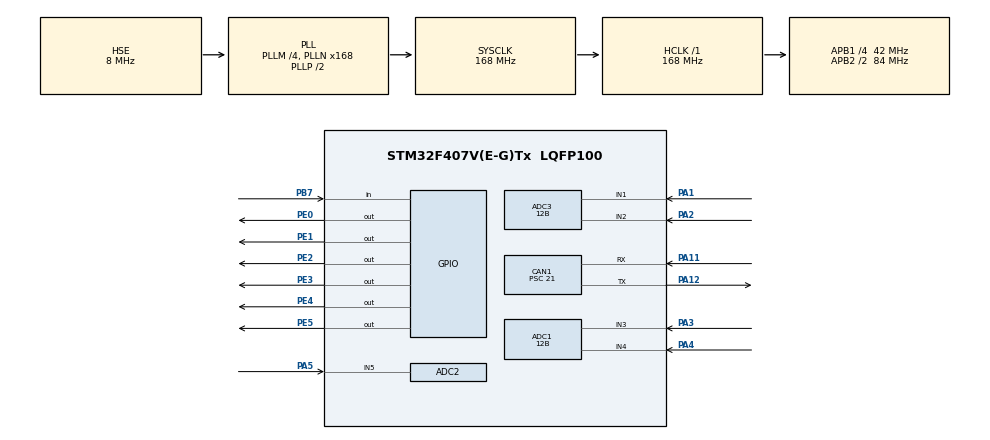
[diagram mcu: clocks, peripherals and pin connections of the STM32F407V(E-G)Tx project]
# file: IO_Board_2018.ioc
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ADC1.Channel-0\#ChannelRegularConversion=ADC_CHANNEL_3
ADC1.Channel-1\#ChannelRegularConversion=ADC_CHANNEL_4
ADC1.ClockPrescaler=ADC_CLOCK_SYNC_PCLK_DIV4
ADC1.ContinuousConvMode=DISABLE
ADC1.DMAContinuousRequests=DISABLE
ADC1.DataAlign=ADC_DATAALIGN_RIGHT
ADC1.DiscontinuousConvMode=ENABLE
ADC1.EOCSelection=ADC_EOC_SINGLE_CONV
ADC1.EnableAnalogWatchDog=false
ADC1.ExternalTrigConv=ADC_SOFTWARE_START
ADC1.ExternalTrigConvEdge=ADC_EXTERNALTRIGCONVEDGE_NONE
ADC1.InjNumberOfConversion=0
ADC1.NbrOfConversion=2
ADC1.NbrOfConversionFlag=1
ADC1.NbrOfDiscConversion=1
ADC1.Rank-0\#ChannelRegularConversion=1
ADC1.Rank-1\#ChannelRegularConversion=2
ADC1.Resolution=ADC_RESOLUTION_12B
ADC1.SamplingTime-0\#ChannelRegularConversion=ADC_SAMPLETIME_3CYCLES
ADC1.SamplingTime-1\#ChannelRegularConversion=ADC_SAMPLETIME_3CYCLES
ADC1.ScanConvMode=ENABLE
ADC1.master=1
ADC2.Channel-0\#ChannelRegularConversion=ADC_CHANNEL_5
ADC2.ClockPrescaler=ADC_CLOCK_SYNC_PCLK_DIV4
ADC2.ContinuousConvMode=DISABLE
ADC2.DMAContinuousRequests=DISABLE
ADC2.DataAlign=ADC_DATAALIGN_RIGHT
ADC2.DiscontinuousConvMode=DISABLE
ADC2.EOCSelection=ADC_EOC_SEQ_CONV
ADC2.EnableAnalogWatchDog=false
ADC2.ExternalTrigConv=ADC_SOFTWARE_START
ADC2.ExternalTrigConvEdge=ADC_EXTERNALTRIGCONVEDGE_NONE
ADC2.InjNumberOfConversion=0
ADC2.NbrOfConversion=1
ADC2.NbrOfConversionFlag=1
ADC2.Rank-0\#ChannelRegularConversion=1
ADC2.Resolution=ADC_RESOLUTION_12B
ADC2.SamplingTime-0\#ChannelRegularConversion=ADC_SAMPLETIME_3CYCLES
ADC2.ScanConvMode=DISABLE
ADC3.Channel-0\#ChannelRegularConversion=ADC_CHANNEL_1
ADC3.Channel-1\#ChannelRegularConversion=ADC_CHANNEL_2
ADC3.ClockPrescaler=ADC_CLOCK_SYNC_PCLK_DIV4
ADC3.ContinuousConvMode=DISABLE
ADC3.DMAContinuousRequests=DISABLE
ADC3.DataAlign=ADC_DATAALIGN_RIGHT
ADC3.DiscontinuousConvMode=ENABLE
ADC3.EOCSelection=ADC_EOC_SINGLE_CONV
ADC3.EnableAnalogWatchDog=false
ADC3.ExternalTrigConv=ADC_SOFTWARE_START
ADC3.ExternalTrigConvEdge=ADC_EXTERNALTRIGCONVEDGE_NONE
ADC3.InjNumberOfConversion=0
ADC3.NbrOfConversion=2
ADC3.NbrOfConversionFlag=1
ADC3.Rank-0\#ChannelRegularConversion=1
ADC3.Rank-1\#ChannelRegularConversion=2
ADC3.Resolution=ADC_RESOLUTION_12B
ADC3.SamplingTime-0\#ChannelRegularConversion=ADC_SAMPLETIME_3CYCLES
ADC3.SamplingTime-1\#ChannelRegularConversion=ADC_SAMPLETIME_3CYCLES
ADC3.ScanConvMode=ENABLE
CAN1.CalculateTimeBit=1500
CAN1.CalculateTimeQuantum=500.0
CAN1.Prescaler=21
CAN1.TimeSeg1=CAN_BS1_2TQ
CAN1.TimeSeg2=CAN_BS2_2TQ
Mcu.Family=STM32F4
Mcu.Name=STM32F407V(E-G)Tx
Mcu.Package=LQFP100
NVIC.PriorityGroup=NVIC_PRIORITYGROUP_4
PA1.Signal=ADCx_IN1
PA11.Mode=Master
PA11.Signal=CAN1_RX
PA12.Mode=Master
PA12.Signal=CAN1_TX
PA13.Mode=Serial_Wire
PA13.Signal=SYS_JTMS-SWDIO
PA14.Mode=Serial_Wire
PA14.Signal=SYS_JTCK-SWCLK
PA2.Signal=ADCx_IN2
PA3.Signal=ADCx_IN3
PA4.Signal=ADCx_IN4
PA5.Signal=ADCx_IN5
PB7.Signal=GPIO_Input
PE0.Signal=GPIO_Output
PE1.Signal=GPIO_Output
PE2.Signal=GPIO_Output
PE3.Signal=GPIO_Output
PE4.Signal=GPIO_Output
PE5.Signal=GPIO_Output
PH0-OSC_IN.Mode=HSE-External-Oscillator
PH0-OSC_IN.Signal=RCC_OSC_IN
PH1-OSC_OUT.Mode=HSE-External-Oscillator
PH1-OSC_OUT.Signal=RCC_OSC_OUT
ProjectManager.HeapSize=0x200
ProjectManager.StackSize=0x400
ProjectManager.TargetToolchain=TrueSTUDIO
RCC.48MHZClocksFreq_Value=84000000
RCC.AHBFreq_Value=168000000
RCC.APB1CLKDivider=RCC_HCLK_DIV4
RCC.APB1Freq_Value=42000000
RCC.APB1TimFreq_Value=84000000
RCC.APB2CLKDivider=RCC_HCLK_DIV2
RCC.APB2Freq_Value=84000000
RCC.APB2TimFreq_Value=168000000
RCC.CortexFreq_Value=168000000
RCC.HCLKFreq_Value=168000000
RCC.HSE_VALUE=8000000
RCC.HSI_VALUE=16000000
RCC.LSE_VALUE=32768
RCC.PLLM=4
RCC.PLLN=168
RCC.PLLSourceVirtual=RCC_PLLSOURCE_HSE
RCC.SYSCLKFreq_VALUE=168000000
RCC.SYSCLKSource=RCC_SYSCLKSOURCE_PLLCLK
RCC.VCOOutputFreq_Value=336000000
SH.ADCx_IN1.0=ADC3_IN1,IN1
SH.ADCx_IN2.0=ADC3_IN2,IN2
SH.ADCx_IN3.0=ADC1_IN3,IN3
SH.ADCx_IN4.0=ADC1_IN4,IN4
SH.ADCx_IN5.0=ADC2_IN5,IN5
board=IO_Board_2018

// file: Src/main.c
/**
  ******************************************************************************
  * @file           : main.c
  * @brief          : Main program body
  ******************************************************************************
  ** This notice applies to any and all portions of this file
  * that are not between comment pairs USER CODE BEGIN and
  * USER CODE END. Other portions of this file, whether
  * inserted by the user or by software development tools
  * are owned by their respective copyright owners.
  *
  * COPYRIGHT(c) 2018 STMicroelectronics
  *
  * Redistribution and use in source and binary forms, with or without modification,
  * are permitted provided that the following conditions are met:
  *   1. Redistributions of source code must retain the above copyright notice,
  *      this list of conditions and the following disclaimer.
  *   2. Redistributions in binary form must reproduce the above copyright notice,
  *      this list of conditions and the following disclaimer in the documentation
  *      and/or other materials provided with the distribution.
  *   3. Neither the name of STMicroelectronics nor the names of its contributors
  *      may be used to endorse or promote products derived from this software
  *      without specific prior written permission.
  *
  * THIS SOFTWARE IS PROVIDED BY THE COPYRIGHT HOLDERS AND CONTRIBUTORS "AS IS"
  * AND ANY EXPRESS OR IMPLIED WARRANTIES, INCLUDING, BUT NOT LIMITED TO, THE
  * IMPLIED WARRANTIES OF MERCHANTABILITY AND FITNESS FOR A PARTICULAR PURPOSE ARE
  * DISCLAIMED. IN NO EVENT SHALL THE COPYRIGHT HOLDER OR CONTRIBUTORS BE LIABLE
  * FOR ANY DIRECT, INDIRECT, INCIDENTAL, SPECIAL, EXEMPLARY, OR CONSEQUENTIAL
  * DAMAGES (INCLUDING, BUT NOT LIMITED TO, PROCUREMENT OF SUBSTITUTE GOODS OR
  * SERVICES; LOSS OF USE, DATA, OR PROFITS; OR BUSINESS INTERRUPTION) HOWEVER
  * CAUSED AND ON ANY THEORY OF LIABILITY, WHETHER IN CONTRACT, STRICT LIABILITY,
  * OR TORT (INCLUDING NEGLIGENCE OR OTHERWISE) ARISING IN ANY WAY OUT OF THE USE
  * OF THIS SOFTWARE, EVEN IF ADVISED OF THE POSSIBILITY OF SUCH DAMAGE.
  *
  ******************************************************************************
  */
#include "main.h"
#include "stm32f4xx_hal.h"
#include "adc.h"
#include "can.h"
#include "gpio.h"

/* USER CODE BEGIN Includes */
#include "io.h"
#include "scheduler.h"

ADC_HandleTypeDef hadc1;
ADC_HandleTypeDef hadc2;
ADC_HandleTypeDef hadc3;
/* USER CODE END Includes */

/* USER CODE BEGIN PV */
/* Private variables ---------------------------------------------------------*/

/* USER CODE END PV */

void SystemClock_Config(void);

/* USER CODE BEGIN PFP */
/* Private function prototypes -----------------------------------------------*/

/* USER CODE END PFP */

int main(void)
{

  /* MCU Configuration----------------------------------------------------------*/

  /* Reset of all peripherals, Initializes the Flash interface and the Systick. */
  HAL_Init();

  /* Configure the system clock */
  SystemClock_Config();

  /* Initialize all configured peripherals */
  MX_GPIO_Init();
  MX_ADC1_Init();
  MX_ADC2_Init();
  MX_ADC3_Init();
  MX_CAN1_Init();
  /* USER CODE BEGIN 2 */
  Init_MyCAN();
  init();
  Schedule schedule;
  MakeSchedule(&schedule, 3);
  AddTask(&schedule, &mainLoop, 437);
  AddTask(&schedule, &sendCANStatuses, 758);
  AddTask(&schedule, &sendHeartbeat, 1000);
  /* USER CODE END 2 */

  /* Infinite loop */
  /* USER CODE BEGIN WHILE */
  while (1)
  {
	  RunSchedule(&schedule);
  }
  /* USER CODE END WHILE */

  /* USER CODE BEGIN 3 */
  DeleteSchedule(schedule);
  /* USER CODE END 3 */

}

void SystemClock_Config(void)
{

  RCC_OscInitTypeDef RCC_OscInitStruct;
  RCC_ClkInitTypeDef RCC_ClkInitStruct;

    /**Configure the main internal regulator output voltage
    */
  __HAL_RCC_PWR_CLK_ENABLE();

  __HAL_PWR_VOLTAGESCALING_CONFIG(PWR_REGULATOR_VOLTAGE_SCALE1);

    /**Initializes the CPU, AHB and APB busses clocks
    */
  RCC_OscInitStruct.OscillatorType = RCC_OSCILLATORTYPE_HSE;
  RCC_OscInitStruct.HSEState = RCC_HSE_ON;
  RCC_OscInitStruct.PLL.PLLState = RCC_PLL_ON;
  RCC_OscInitStruct.PLL.PLLSource = RCC_PLLSOURCE_HSE;
  RCC_OscInitStruct.PLL.PLLM = 4;
  RCC_OscInitStruct.PLL.PLLN = 168;
  RCC_OscInitStruct.PLL.PLLP = RCC_PLLP_DIV2;
  RCC_OscInitStruct.PLL.PLLQ = 4;
  if (HAL_RCC_OscConfig(&RCC_OscInitStruct) != HAL_OK)
  {
    _Error_Handler(__FILE__, __LINE__);
  }

    /**Initializes the CPU, AHB and APB busses clocks
    */
  RCC_ClkInitStruct.ClockType = RCC_CLOCKTYPE_HCLK|RCC_CLOCKTYPE_SYSCLK
                              |RCC_CLOCKTYPE_PCLK1|RCC_CLOCKTYPE_PCLK2;
  RCC_ClkInitStruct.SYSCLKSource = RCC_SYSCLKSOURCE_PLLCLK;
  RCC_ClkInitStruct.AHBCLKDivider = RCC_SYSCLK_DIV1;
  RCC_ClkInitStruct.APB1CLKDivider = RCC_HCLK_DIV4;
  RCC_ClkInitStruct.APB2CLKDivider = RCC_HCLK_DIV2;

  if (HAL_RCC_ClockConfig(&RCC_ClkInitStruct, FLASH_LATENCY_5) != HAL_OK)
  {
    _Error_Handler(__FILE__, __LINE__);
  }

    /**Configure the Systick interrupt time
    */
  HAL_SYSTICK_Config(HAL_RCC_GetHCLKFreq()/1000);

    /**Configure the Systick
    */
  HAL_SYSTICK_CLKSourceConfig(SYSTICK_CLKSOURCE_HCLK);

  /* SysTick_IRQn interrupt configuration */
  HAL_NVIC_SetPriority(SysTick_IRQn, 0, 0);
}

void _Error_Handler(char *file, int line)
{
  while(1)
  {
  }
}

/************************ (C) COPYRIGHT STMicroelectronics *****END OF FILE****/
